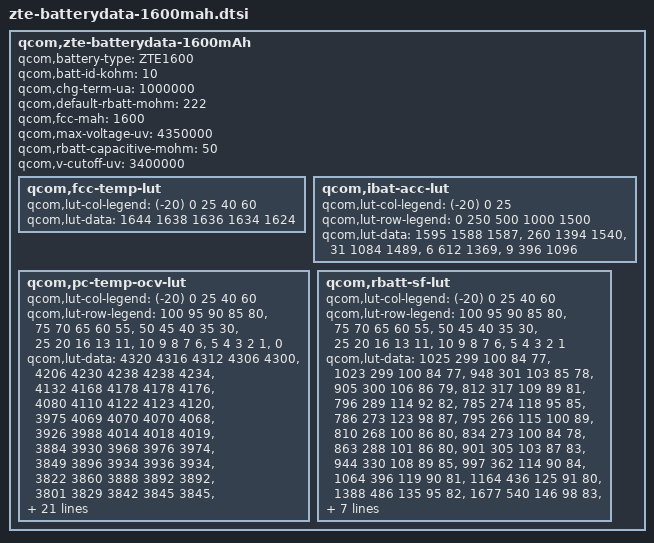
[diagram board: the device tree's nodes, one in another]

qcom,zte-batterydata-1600mAh {
	qcom,battery-type = "ZTE1600";
	qcom,batt-id-kohm = <10>;
	qcom,chg-term-ua = <1000000>;
	qcom,default-rbatt-mohm = <222>;
	qcom,fcc-mah = <1600>;
	qcom,max-voltage-uv = <4350000>;
	qcom,rbatt-capacitive-mohm = <50>;
	qcom,v-cutoff-uv = <3400000>;

	qcom,fcc-temp-lut {
		qcom,lut-col-legend = <(-20) 0 25 40 60>;
		qcom,lut-data = <1644 1638 1636 1634 1624>;
	};

	qcom,ibat-acc-lut {
		qcom,lut-col-legend = <(-20) 0 25>;
		qcom,lut-row-legend = <0 250 500 1000 1500>;
		qcom,lut-data = <1595 1588 1587>,
				<260 1394 1540>,
				<31 1084 1489>,
				<6 612 1369>,
				<9 396 1096>;
	};

	qcom,pc-temp-ocv-lut {
		qcom,lut-col-legend = <(-20) 0 25 40 60>;
		qcom,lut-row-legend = <100 95 90 85 80>,
					<75 70 65 60 55>,
					<50 45 40 35 30>,
					<25 20 16 13 11>,
					<10 9 8 7 6>,
					<5 4 3 2 1>,
					<0>;
		qcom,lut-data = <4320 4316 4312 4306 4300>,
				<4206 4230 4238 4238 4234>,
				<4132 4168 4178 4178 4176>,
				<4080 4110 4122 4123 4120>,
				<3975 4069 4070 4070 4068>,
				<3926 3988 4014 4018 4019>,
				<3884 3930 3968 3976 3974>,
				<3849 3896 3934 3936 3934>,
				<3822 3860 3888 3892 3892>,
				<3801 3829 3842 3845 3845>,
				<3782 3806 3815 3816 3816>,
				<3764 3790 3794 3795 3794>,
				<3746 3780 3780 3780 3779>,
				<3730 3772 3773 3769 3767>,
				<3714 3760 3768 3761 3753>,
				<3698 3744 3758 3749 3734>,
				<3682 3718 3738 3728 3714>,
				<3662 3691 3708 3701 3688>,
				<3642 3670 3684 3679 3670>,
				<3623 3654 3673 3672 3664>,
				<3610 3642 3662 3664 3660>,
				<3592 3625 3646 3652 3652>,
				<3571 3606 3624 3632 3636>,
				<3546 3584 3597 3605 3612>,
				<3514 3559 3570 3576 3581>,
				<3477 3526 3536 3536 3536>,
				<3434 3480 3483 3480 3478>,
				<3380 3418 3416 3412 3408>,
				<3309 3338 3334 3329 3325>,
				<3204 3223 3224 3214 3210>,
				<3000 3026 3022 3000 3000>;
	};

	qcom,rbatt-sf-lut {
		qcom,lut-col-legend = <(-20) 0 25 40 60>;
		qcom,lut-row-legend = <100 95 90 85 80>,
					<75 70 65 60 55>,
					<50 45 40 35 30>,
					<25 20 16 13 11>,
					<10 9 8 7 6>,
					<5 4 3 2 1>;
		qcom,lut-data = <1025 299 100 84 77>,
				<1023 299 100 84 77>,
				<948 301 103 85 78>,
				<905 300 106 86 79>,
				<812 317 109 89 81>,
				<796 289 114 92 82>,
				<785 274 118 95 85>,
				<786 273 123 98 87>,
				<795 266 115 100 89>,
				<810 268 100 86 80>,
				<834 273 100 84 78>,
				<863 288 101 86 80>,
				<901 305 103 87 83>,
				<944 330 108 89 85>,
				<997 362 114 90 84>,
				<1064 396 119 90 81>,
				<1164 436 125 91 80>,
				<1388 486 135 95 82>,
				<1677 540 146 98 83>,
				<2049 577 160 100 84>,
				<2418 614 178 107 86>,
				<2931 652 196 117 87>,
				<3649 699 208 125 92>,
				<4660 756 215 130 95>,
				<6101 832 222 131 96>,
				<8221 931 226 129 93>,
				<11308 1133 232 130 94>,
				<15975 1549 250 135 96>,
				<23110 2201 282 148 102>,
				<34550 3332 334 167 112>;
	};
};
